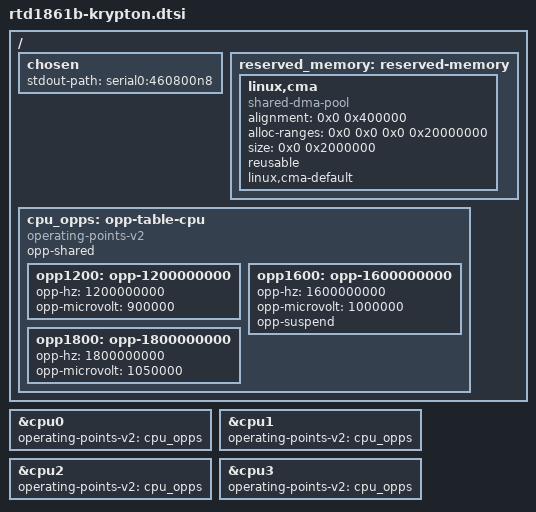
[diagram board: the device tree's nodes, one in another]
// SPDX-License-Identifier: GPL-2.0
/*
 * Realtek RTD1861B Krypton EVB
 *
 * Copyright (c) 2024 Realtek Semiconductor Corp.
 */

/dts-v1/;

#include "rtd1861.dtsi"

/ {
	chosen {
		stdout-path = "serial0:460800n8";
	};

	reserved_memory: reserved-memory {
		#address-cells = <2>;
		#size-cells = <2>;
		ranges;

		linux,cma {
			compatible = "shared-dma-pool";
			alignment = <0x0 0x400000>;
			alloc-ranges = <0x0 0x0 0x0 0x20000000>;
			size = <0x0 0x2000000>;
			reusable;
			linux,cma-default;
		};
	};

	cpu_opps: opp-table-cpu {
		compatible = "operating-points-v2";
		opp-shared;

		opp1200: opp-1200000000 {
			opp-hz = /bits/ 64 <1200000000>;
			opp-microvolt = <900000>;
		};

		opp1600: opp-1600000000 {
			opp-hz = /bits/ 64 <1600000000>;
			opp-microvolt = <1000000>;
			opp-suspend;
		};

		opp1800: opp-1800000000 {
			opp-hz = /bits/ 64 <1800000000>;
			opp-microvolt = <1050000>;
		};
	};
};

&cpu0 {
	operating-points-v2 = <&cpu_opps>;
	#cooling-cells = <2>;
};

&cpu1 {
	operating-points-v2 = <&cpu_opps>;
	#cooling-cells = <2>;
};

&cpu2 {
	operating-points-v2 = <&cpu_opps>;
	#cooling-cells = <2>;
};

&cpu3 {
	operating-points-v2 = <&cpu_opps>;
	#cooling-cells = <2>;
};
